AUTOSAR XML (schema 4-0-3)
# Copyright 2010 - 2012 ETAS GmbH.
package /TGen_CaseStudy1
  data type mapping set dtm1: mode-request-type-map{implementation-data-type=uint16, mode-group=mg1}
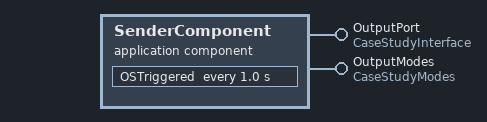
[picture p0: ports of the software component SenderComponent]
  application sw component type SenderComponent
    provide port OutputPort: provided-interface=CaseStudyInterface
    provide port OutputModes: mode-switch-sender-com-spec{mode-group=mdg1, queue-length=1}, provided-interface=CaseStudyModes
    behavior IBSenderComponent: data-type-mapping=dtm1, supports-multiple-instantiation=true
      timing event PollPeriod: start-on-event=OSTriggered, period=1.0
      per instance memory ExecutionCount: type=ExecutionCountType, type-definition=SInt16
      runnable OSTriggered: symbol=Sender_OSTriggered
        data-send-points:
          access dsp_OutputPort_CaseStudyData: accessed-variable=OutputPort.CaseStudyData
        mode switch point msp_OutputModes_mdg1: mode-group=OutputModes.mdg1
  swc implementation IMPSenderComponent: behavior=IBSenderComponent
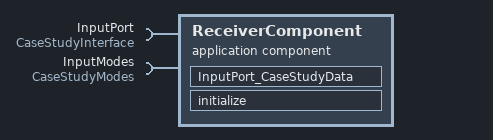
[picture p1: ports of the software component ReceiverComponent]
  application sw component type ReceiverComponent
    require port InputPort: required-interface=CaseStudyInterface
    require port InputModes: required-interface=CaseStudyModes
    behavior IBReceiverComponent: data-type-mapping=dtm1, supports-multiple-instantiation=true
      data received event InputPort_CaseStudyData_Event: start-on-event=InputPort_CaseStudyData, data=InputPort.CaseStudyData
      swc mode switch event mse1: start-on-event=initialize, activation=ON-ENTRY, mode=InputModes.mdg1.imode
      runnable InputPort_CaseStudyData: symbol=Receiver_InputPort_CaseStudyData
        data-receive-point-by-arguments:
          access drp_InputPort_CaseStudyData: accessed-variable=InputPort.CaseStudyData
      runnable initialize: symbol=Receiver_initialize
  swc implementation IMPReceiverComponent: behavior=IBReceiverComponent
  sender receiver interface CaseStudyInterface
    data CaseStudyData: type=uint8
  mode switch interface CaseStudyModes
    mode group mdg1: type=mg1
  mode declaration group mg1: category=ALPHABETIC_ORDER, initial-mode=imode
    mode imode
    mode run_mode
  ecu instance ECUI_intra
    can communication connector comCon1
  system sys_intra
    system mapping mapping
      sw-mappings:
        swc to ecu mapping map_ECUI_intra: component=[mySWComp.SenderInstance, mySWComp.ReceiverInstance], ecu-instance=ECUI_intra
    root-software-compositions:
      root sw composition prototype mySWComp: software-composition=Compo
  composition sw component type Compo
    component SenderInstance: type=SenderComponent
    component ReceiverInstance: type=ReceiverComponent
    connect SenderInstance.OutputPort -> ReceiverInstance.InputPort
    connect SenderInstance.OutputModes -> ReceiverInstance.InputModes
